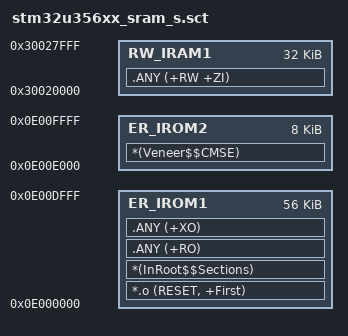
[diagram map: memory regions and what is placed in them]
; *************************************************************
; *** Scatter-Loading Description File generated by uVision ***
; *************************************************************

LR_IROM1 0x0E000000 0x0000E000  {    ; load region size_region
  ER_IROM1 0x0E000000 0x0000E000  {  ; load address = execution address
   *.o (RESET, +First)
   *(InRoot$$Sections)
   .ANY (+RO)
   .ANY (+XO)
  }
  RW_IRAM1 0x30020000 0x00008000  {  ; RW data
   .ANY (+RW +ZI)
  }
}

LR_IROM2 0x0E00E000 0x00002000  {    ; load region size_region
  ER_IROM2 0x0E00E000 0x00002000  {  ; load address = execution address
   *(Veneer$$CMSE)                   ; check with partition.h
  }
}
